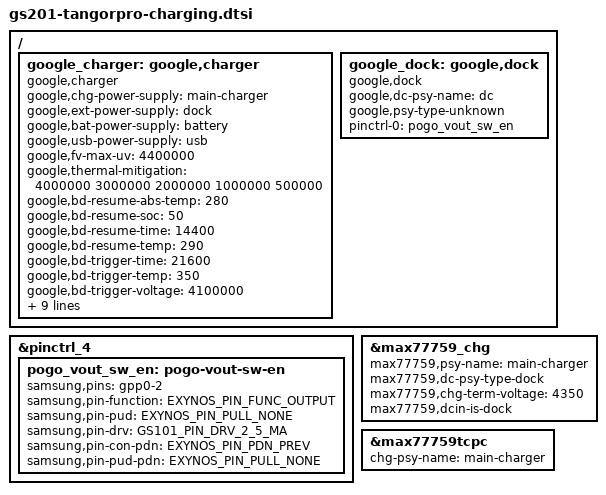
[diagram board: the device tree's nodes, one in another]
// SPDX-License-Identifier: GPL-2.0-only
/*
 * Battery device tree entries specific to tangorpro
 *
 * Copyright 2022 Google,LLC
 *
 */

/ {
	fragment@charging {
		target-path = "/";
		__overlay__ {

			google_charger: google,charger {
				status = "okay";
				compatible = "google,charger";
				#cooling-cells = <2>;

				google,chg-power-supply = "main-charger"; /* max77759-charger */
				google,ext-power-supply = "dock";

				google,bat-power-supply = "battery";
				google,usb-power-supply = "usb";

				google,fv-max-uv = <4400000>;

				google,thermal-mitigation = <4000000 3000000 2000000 1000000 500000>;

				/* b/170700459 thresholds, updated in b/191070950 */
				google,bd-resume-abs-temp = <280>;
				google,bd-resume-soc = <50>;
				google,bd-resume-time = <14400>;  /* 4 hours */
				google,bd-resume-temp = <290>;
				google,bd-trigger-time = <21600>; /* 6 hours */
				google,bd-trigger-temp = <350>;
				google,bd-trigger-voltage = <4100000>;
				google,bd-recharge-voltage = <4080000>;
				google,bd-drainto-soc = <80>;
				google,bd-recharge-soc = <79>;
				/* Enable TEMP-DEFEND */
				google,bd-temp-enable;

				/* dock_defend */
				google,dd-charge-stop-level = <90>;
				google,dd-charge-start-level = <87>;
				google,dd-state = <0>;    /* DOCK_DEFEND_ENABLED */
				google,dd-settings = <1>; /* DOCK_DEFEND_USER_ENABLED */
				google,dd-trigger-time = <60>; /* 1 mins */
			};

			google_dock: google,dock {
				status = "okay";
				compatible = "google,dock";
				google,dc-psy-name = "dc";
				google,psy-type-unknown;
				pinctrl-names = "default";
				pinctrl-0 = <&pogo_vout_sw_en>;
			};

		};
	};
};

&pinctrl_4 {
	/* XAPC_GPIO1 POGO_VOUT_SW_EN */
	pogo_vout_sw_en: pogo-vout-sw-en {
		samsung,pins = "gpp0-2";
		samsung,pin-function = <EXYNOS_PIN_FUNC_OUTPUT>;
		samsung,pin-pud = <EXYNOS_PIN_PULL_NONE>;
		samsung,pin-drv = <GS101_PIN_DRV_2_5_MA>;
		samsung,pin-con-pdn = <EXYNOS_PIN_PDN_PREV>;
		samsung,pin-pud-pdn = <EXYNOS_PIN_PULL_NONE>;
	};
};

&max77759_chg {
	max77759,psy-name = "main-charger";
	max77759,dc-psy-type-dock;

	max77759,chg-term-voltage = <4350>;

	max77759,dcin-is-dock;
};

&max77759tcpc {
	chg-psy-name = "main-charger";
};
